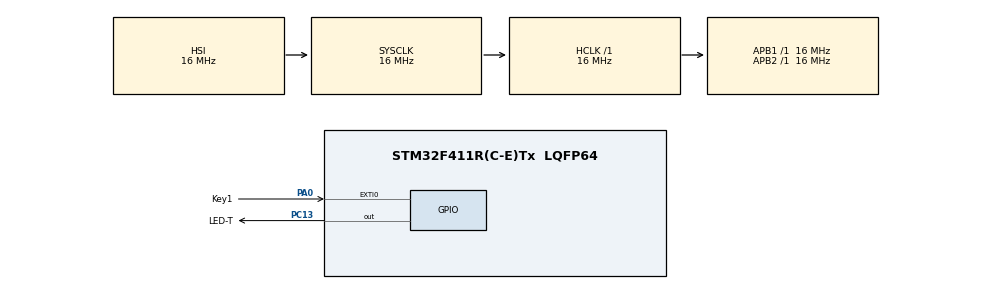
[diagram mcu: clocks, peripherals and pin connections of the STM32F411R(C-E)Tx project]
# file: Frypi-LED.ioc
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Mcu.Family=STM32F4
Mcu.Name=STM32F411R(C-E)Tx
Mcu.Package=LQFP64
NVIC.EXTI0_IRQn=true\:0\:0\:false\:false\:true\:true\:true\:true
NVIC.PriorityGroup=NVIC_PRIORITYGROUP_4
NVIC.TIM2_IRQn=true\:0\:0\:false\:false\:true\:true\:true\:true
PA0-WKUP.GPIO_Label=Key1
PA0-WKUP.GPIO_ModeDefaultEXTI=GPIO_MODE_IT_FALLING
PA0-WKUP.GPIO_PuPd=GPIO_PULLUP
PA0-WKUP.Signal=GPXTI0
PA13.Mode=Serial_Wire
PA13.Signal=SYS_JTMS-SWDIO
PA14.Mode=Serial_Wire
PA14.Signal=SYS_JTCK-SWCLK
PC13-ANTI_TAMP.GPIO_Label=LED-T
PC13-ANTI_TAMP.GPIO_PuPd=GPIO_PULLUP
PC13-ANTI_TAMP.Signal=GPIO_Output
ProjectManager.HeapSize=0x200
ProjectManager.StackSize=0x400
ProjectManager.TargetToolchain=MDK-ARM V5.32
RCC.AHBFreq_Value=16000000
RCC.APB1Freq_Value=16000000
RCC.APB1TimFreq_Value=16000000
RCC.APB2Freq_Value=16000000
RCC.APB2TimFreq_Value=16000000
RCC.CortexFreq_Value=16000000
RCC.HCLKFreq_Value=16000000
RCC.HSE_VALUE=25000000
RCC.HSI_VALUE=16000000
RCC.LSE_VALUE=32768
RCC.SYSCLKFreq_VALUE=16000000
RCC.VCOOutputFreq_Value=192000000
TIM2.Period=499
TIM2.Prescaler=15999
VP_TIM2_VS_ClockSourceINT.Mode=Internal
board=custom

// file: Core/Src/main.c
/* USER CODE BEGIN Header */
/**
  ******************************************************************************
  * @file           : main.c
  * @brief          : Main program body
  ******************************************************************************
  * @attention
  *
  * Copyright (c) 2026 STMicroelectronics.
  * All rights reserved.
  *
  * This software is licensed under terms that can be found in the LICENSE file
  * in the root directory of this software component.
  * If no LICENSE file comes with this software, it is provided AS-IS.
  *
  ******************************************************************************
  */
/* USER CODE END Header */
#include "main.h"

/* USER CODE BEGIN PD */

#define KEY_DEBOUNCE_MS 20U

/* USER CODE END PD */

TIM_HandleTypeDef htim2;

/* USER CODE BEGIN PV */

static GPIO_PinState raw_key_state = GPIO_PIN_SET;
static GPIO_PinState stable_key_state = GPIO_PIN_SET;
static uint32_t key_state_change_tick = 0U;
static uint32_t last_press_tick = 0;
static volatile uint8_t blink_enabled = 1;

/* USER CODE END PV */

void SystemClock_Config(void);
static void MX_GPIO_Init(void);
static void MX_TIM2_Init(void);

int main(void)
{

  /* MCU Configuration--------------------------------------------------------*/

  /* Reset of all peripherals, Initializes the Flash interface and the Systick. */
  HAL_Init();

  /* Configure the system clock */
  SystemClock_Config();

  /* Initialize all configured peripherals */
  MX_GPIO_Init();
  MX_TIM2_Init();
  /* USER CODE BEGIN 2 */
  HAL_TIM_Base_Start_IT(&htim2);
  raw_key_state = HAL_GPIO_ReadPin(Key1_GPIO_Port, Key1_Pin);
  stable_key_state = raw_key_state;
  key_state_change_tick = HAL_GetTick();

  /* USER CODE END 2 */

  /* Infinite loop */
  while (1)
  {

  }
}

void SystemClock_Config(void)
{
  RCC_OscInitTypeDef RCC_OscInitStruct = {0};
  RCC_ClkInitTypeDef RCC_ClkInitStruct = {0};

  /** Configure the main internal regulator output voltage
  */
  __HAL_RCC_PWR_CLK_ENABLE();
  __HAL_PWR_VOLTAGESCALING_CONFIG(PWR_REGULATOR_VOLTAGE_SCALE1);

  /** Initializes the RCC Oscillators according to the specified parameters
  * in the RCC_OscInitTypeDef structure.
  */
  RCC_OscInitStruct.OscillatorType = RCC_OSCILLATORTYPE_HSI;
  RCC_OscInitStruct.HSIState = RCC_HSI_ON;
  RCC_OscInitStruct.HSICalibrationValue = RCC_HSICALIBRATION_DEFAULT;
  RCC_OscInitStruct.PLL.PLLState = RCC_PLL_NONE;
  if (HAL_RCC_OscConfig(&RCC_OscInitStruct) != HAL_OK)
  {
    Error_Handler();
  }

  /** Initializes the CPU, AHB and APB buses clocks
  */
  RCC_ClkInitStruct.ClockType = RCC_CLOCKTYPE_HCLK|RCC_CLOCKTYPE_SYSCLK
                              |RCC_CLOCKTYPE_PCLK1|RCC_CLOCKTYPE_PCLK2;
  RCC_ClkInitStruct.SYSCLKSource = RCC_SYSCLKSOURCE_HSI;
  RCC_ClkInitStruct.AHBCLKDivider = RCC_SYSCLK_DIV1;
  RCC_ClkInitStruct.APB1CLKDivider = RCC_HCLK_DIV1;
  RCC_ClkInitStruct.APB2CLKDivider = RCC_HCLK_DIV1;

  if (HAL_RCC_ClockConfig(&RCC_ClkInitStruct, FLASH_LATENCY_0) != HAL_OK)
  {
    Error_Handler();
  }
}

static void MX_TIM2_Init(void)
{

  TIM_ClockConfigTypeDef sClockSourceConfig = {0};
  TIM_MasterConfigTypeDef sMasterConfig = {0};

  htim2.Instance = TIM2;
  htim2.Init.Prescaler = 15999;
  htim2.Init.CounterMode = TIM_COUNTERMODE_UP;
  htim2.Init.Period = 499;
  htim2.Init.ClockDivision = TIM_CLOCKDIVISION_DIV1;
  htim2.Init.AutoReloadPreload = TIM_AUTORELOAD_PRELOAD_DISABLE;
  if (HAL_TIM_Base_Init(&htim2) != HAL_OK)
  {
    Error_Handler();
  }
  sClockSourceConfig.ClockSource = TIM_CLOCKSOURCE_INTERNAL;
  if (HAL_TIM_ConfigClockSource(&htim2, &sClockSourceConfig) != HAL_OK)
  {
    Error_Handler();
  }
  sMasterConfig.MasterOutputTrigger = TIM_TRGO_RESET;
  sMasterConfig.MasterSlaveMode = TIM_MASTERSLAVEMODE_DISABLE;
  if (HAL_TIMEx_MasterConfigSynchronization(&htim2, &sMasterConfig) != HAL_OK)
  {
    Error_Handler();
  }

}

static void MX_GPIO_Init(void)
{
  GPIO_InitTypeDef GPIO_InitStruct = {0};

  /* GPIO Ports Clock Enable */
  __HAL_RCC_GPIOC_CLK_ENABLE();
  __HAL_RCC_GPIOA_CLK_ENABLE();

  /*Configure GPIO pin Output Level */
  HAL_GPIO_WritePin(LED_T_GPIO_Port, LED_T_Pin, GPIO_PIN_RESET);

  /*Configure GPIO pin : LED_T_Pin */
  GPIO_InitStruct.Pin = LED_T_Pin;
  GPIO_InitStruct.Mode = GPIO_MODE_OUTPUT_PP;
  GPIO_InitStruct.Pull = GPIO_PULLUP;
  GPIO_InitStruct.Speed = GPIO_SPEED_FREQ_LOW;
  HAL_GPIO_Init(LED_T_GPIO_Port, &GPIO_InitStruct);

  /*Configure GPIO pin : Key1_Pin */
  GPIO_InitStruct.Pin = Key1_Pin;
  GPIO_InitStruct.Mode = GPIO_MODE_IT_FALLING;
  GPIO_InitStruct.Pull = GPIO_PULLUP;
  HAL_GPIO_Init(Key1_GPIO_Port, &GPIO_InitStruct);

  /* EXTI interrupt init*/
  HAL_NVIC_SetPriority(EXTI0_IRQn, 0, 0);
  HAL_NVIC_EnableIRQ(EXTI0_IRQn);

}

/* USER CODE BEGIN 4 */
void HAL_GPIO_EXTI_Callback(uint16_t GPIO_Pin)
{
    if (GPIO_Pin == Key1_Pin)
    {
        uint32_t now = HAL_GetTick();

        if ((now - last_press_tick) >= 50)
        {
            blink_enabled ^= 1U;
            last_press_tick = now;
        }
    }
}
void HAL_TIM_PeriodElapsedCallback(TIM_HandleTypeDef *htim)
{
    if (htim->Instance == TIM2 && blink_enabled)
    {
        HAL_GPIO_TogglePin(LED_T_GPIO_Port, LED_T_Pin);
    }
}

/* USER CODE END 4 */

void Error_Handler(void)
{
  __disable_irq();
  while (1)
  {
  }
}
